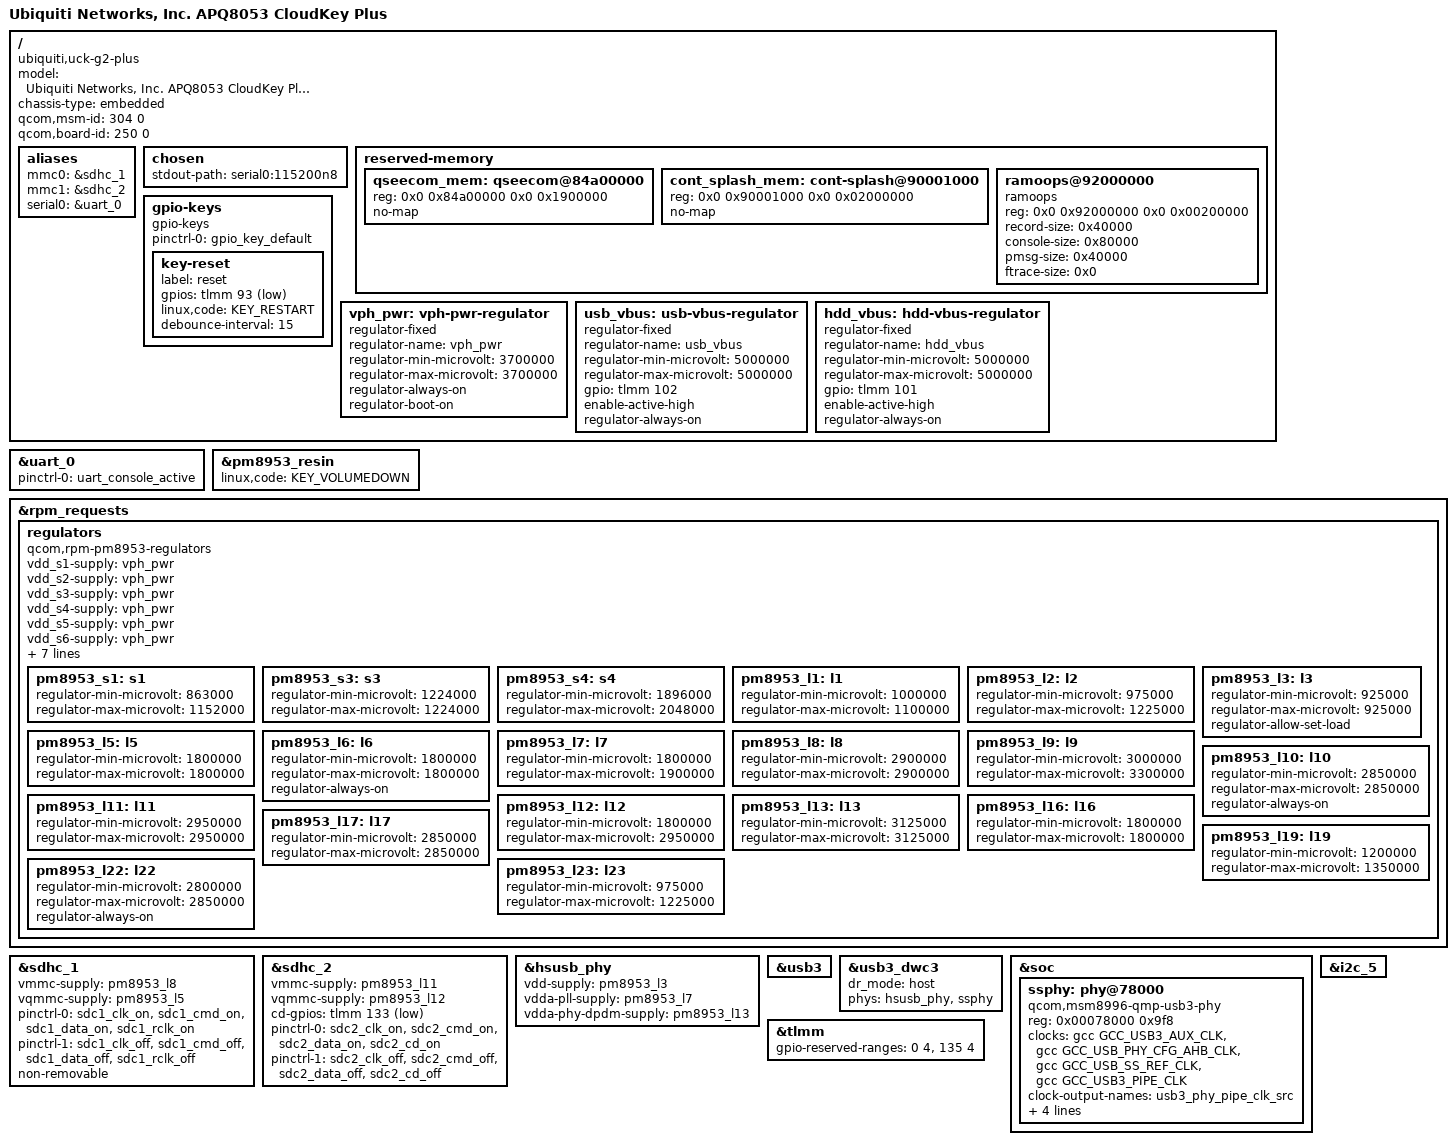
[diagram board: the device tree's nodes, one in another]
// SPDX-License-Identifier: BSD-3-Clause
/*
 * Ubiquiti UniFi Cloud Key Gen2 Plus (UCK G2 Plus, "UCKP")
 * Qualcomm APQ8053 / MSM8953 (Snapdragon 625)
 *
 * Ported to the msm8953-mainline tree from Ubiquiti's GPL vendor DTS
 * (apq8053-ck-plus.dts + msm8953-ck-plus.dtsi).  Minimal bring-up:
 * serial console, eMMC (rootfs), SD card, USB3, PMIC regulators, power/keys.
 */
/dts-v1/;

#include "msm8953.dtsi"
#include "pm8953.dtsi"
#include "pmi8950.dtsi"

/delete-node/ &cont_splash_mem;
/delete-node/ &qseecom_mem;

/ {
	model = "Ubiquiti Networks, Inc. APQ8053 CloudKey Plus";
	compatible = "ubiquiti,uck-g2-plus", "qcom,msm8953";
	chassis-type = "embedded";
	/*
	 * aboot (Qualcomm LK) matches appended DTBs on qcom,msm-id/qcom,board-id.
	 * Device socinfo reports id=304 (0x130), hw_plat=250 (0xfa) -- must match
	 * the stock DTBs or aboot errors with "Couldn't find the suitable DTB!".
	 */
	qcom,msm-id = <304 0>;
	qcom,board-id = <250 0>;

	aliases {
		mmc0 = &sdhc_1;	/* eMMC  (system + appdata) */
		mmc1 = &sdhc_2;	/* microSD */
		serial0 = &uart_0;
	};

	chosen {
		stdout-path = "serial0:115200n8";
	};

	reserved-memory {
		qseecom_mem: qseecom@84a00000 {
			reg = <0x0 0x84a00000 0x0 0x1900000>;
			no-map;
		};

		cont_splash_mem: cont-splash@90001000 {
			reg = <0x0 0x90001000 0x0 0x02000000>;
			no-map;
		};

		/*
		 * Match the vendor ramoops region so pstore survives a crash and
		 * can be read on next boot (visibility into a failed 6.19 boot).
		 * Vendor: ramoops_region@92000000, 2 MiB.
		 */
		ramoops@92000000 {
			compatible = "ramoops";
			reg = <0x0 0x92000000 0x0 0x00200000>;
			record-size = <0x40000>;
			console-size = <0x80000>;
			pmsg-size = <0x40000>;
			ftrace-size = <0x0>;
		};
	};

	gpio-keys {
		compatible = "gpio-keys";
		pinctrl-names = "default";
		pinctrl-0 = <&gpio_key_default>;

		key-reset {
			label = "reset";
			gpios = <&tlmm 93 GPIO_ACTIVE_LOW>;
			linux,code = <KEY_RESTART>;
			debounce-interval = <15>;
		};
	};

	vph_pwr: vph-pwr-regulator {
		compatible = "regulator-fixed";
		regulator-name = "vph_pwr";
		regulator-min-microvolt = <3700000>;
		regulator-max-microvolt = <3700000>;
		regulator-always-on;
		regulator-boot-on;
	};

	/* USB / SATA power enables on the UCK (from vendor DTS) */
	usb_vbus: usb-vbus-regulator {
		compatible = "regulator-fixed";
		regulator-name = "usb_vbus";
		regulator-min-microvolt = <5000000>;
		regulator-max-microvolt = <5000000>;
		gpio = <&tlmm 102 GPIO_ACTIVE_HIGH>;
		enable-active-high;
		regulator-always-on;
	};

	hdd_vbus: hdd-vbus-regulator {
		compatible = "regulator-fixed";
		regulator-name = "hdd_vbus";
		regulator-min-microvolt = <5000000>;
		regulator-max-microvolt = <5000000>;
		gpio = <&tlmm 101 GPIO_ACTIVE_HIGH>;
		enable-active-high;
		regulator-always-on;
	};
};

&uart_0 {
	status = "okay";
	pinctrl-names = "default";
	pinctrl-0 = <&uart_console_active>;
};

&pm8953_resin {
	linux,code = <KEY_VOLUMEDOWN>;
	status = "okay";
};

&rpm_requests {
	regulators {
		compatible = "qcom,rpm-pm8953-regulators";

		vdd_s1-supply = <&vph_pwr>;
		vdd_s2-supply = <&vph_pwr>;
		vdd_s3-supply = <&vph_pwr>;
		vdd_s4-supply = <&vph_pwr>;
		vdd_s5-supply = <&vph_pwr>;
		vdd_s6-supply = <&vph_pwr>;
		vdd_s7-supply = <&vph_pwr>;
		vdd_l1-supply = <&pm8953_s3>;
		vdd_l2_l3-supply = <&pm8953_s3>;
		vdd_l4_l5_l6_l7_l16_l19-supply = <&pm8953_s4>;
		vdd_l8_l11_l12_l13_l14_l15-supply = <&vph_pwr>;
		vdd_l9_l10_l17_l18_l22-supply = <&vph_pwr>;
		vdd_l23-supply = <&pm8953_s3>;

		pm8953_s1: s1 {
			regulator-min-microvolt = <863000>;
			regulator-max-microvolt = <1152000>;
		};

		pm8953_s3: s3 {
			regulator-min-microvolt = <1224000>;
			regulator-max-microvolt = <1224000>;
		};

		pm8953_s4: s4 {
			regulator-min-microvolt = <1896000>;
			regulator-max-microvolt = <2048000>;
		};

		pm8953_l1: l1 {
			regulator-min-microvolt = <1000000>;
			regulator-max-microvolt = <1100000>;
		};

		pm8953_l2: l2 {
			regulator-min-microvolt = <975000>;
			regulator-max-microvolt = <1225000>;
		};

		pm8953_l3: l3 {
			regulator-min-microvolt = <925000>;
			regulator-max-microvolt = <925000>;
			regulator-allow-set-load;
		};

		pm8953_l5: l5 {
			regulator-min-microvolt = <1800000>;
			regulator-max-microvolt = <1800000>;
		};

		pm8953_l6: l6 {
			regulator-min-microvolt = <1800000>;
			regulator-max-microvolt = <1800000>;
			regulator-always-on;
		};

		pm8953_l7: l7 {
			regulator-min-microvolt = <1800000>;
			regulator-max-microvolt = <1900000>;
		};

		pm8953_l8: l8 {
			regulator-min-microvolt = <2900000>;
			regulator-max-microvolt = <2900000>;
		};

		pm8953_l9: l9 {
			regulator-min-microvolt = <3000000>;
			regulator-max-microvolt = <3300000>;
		};

		pm8953_l10: l10 {
			regulator-min-microvolt = <2850000>;
			regulator-max-microvolt = <2850000>;
			regulator-always-on;
		};

		pm8953_l11: l11 {
			regulator-min-microvolt = <2950000>;
			regulator-max-microvolt = <2950000>;
		};

		pm8953_l12: l12 {
			regulator-min-microvolt = <1800000>;
			regulator-max-microvolt = <2950000>;
		};

		pm8953_l13: l13 {
			regulator-min-microvolt = <3125000>;
			regulator-max-microvolt = <3125000>;
		};

		pm8953_l16: l16 {
			regulator-min-microvolt = <1800000>;
			regulator-max-microvolt = <1800000>;
		};

		pm8953_l17: l17 {
			regulator-min-microvolt = <2850000>;
			regulator-max-microvolt = <2850000>;
		};

		pm8953_l19: l19 {
			regulator-min-microvolt = <1200000>;
			regulator-max-microvolt = <1350000>;
		};

		pm8953_l22: l22 {
			regulator-min-microvolt = <2800000>;
			regulator-max-microvolt = <2850000>;
			regulator-always-on;
		};

		pm8953_l23: l23 {
			regulator-min-microvolt = <975000>;
			regulator-max-microvolt = <1225000>;
		};
	};
};

/* eMMC: system rootfs (p44/p46/p47) + the internal 1TB disk */
&sdhc_1 {
	vmmc-supply = <&pm8953_l8>;
	vqmmc-supply = <&pm8953_l5>;

	pinctrl-names = "default", "sleep";
	pinctrl-0 = <&sdc1_clk_on &sdc1_cmd_on &sdc1_data_on &sdc1_rclk_on>;
	pinctrl-1 = <&sdc1_clk_off &sdc1_cmd_off &sdc1_data_off &sdc1_rclk_off>;

	non-removable;
	status = "okay";
};

/* microSD slot */
&sdhc_2 {
	vmmc-supply = <&pm8953_l11>;
	vqmmc-supply = <&pm8953_l12>;

	cd-gpios = <&tlmm 133 GPIO_ACTIVE_LOW>;

	pinctrl-names = "default", "sleep";
	pinctrl-0 = <&sdc2_clk_on &sdc2_cmd_on &sdc2_data_on &sdc2_cd_on>;
	pinctrl-1 = <&sdc2_clk_off &sdc2_cmd_off &sdc2_data_off &sdc2_cd_off>;

	status = "okay";
};

&hsusb_phy {
	vdd-supply = <&pm8953_l3>;
	vdda-pll-supply = <&pm8953_l7>;
	vdda-phy-dpdm-supply = <&pm8953_l13>;

	status = "okay";
};

&usb3 {
	status = "okay";
};

&usb3_dwc3 {
	/*
	 * The mainline dtsi sets `usb-role-switch` with no role-switch-default-mode.
	 * dwc3_drd_init() -> dwc3_setup_role_switch(): no default mode =>
	 * USB_DR_MODE_UNKNOWN => controller defaults to PERIPHERAL. That kills the
	 * internal USB hub, so the AX88179 NIC never enumerates and the box looks
	 * dead. Drop the property (what the mainline msm8953 phones do) so
	 * dr_mode="host" actually takes effect.
	 */
	/delete-property/ usb-role-switch;
	/* The UCK's NIC + SATA live on the SuperSpeed root hub; the mainline dtsi
	 * caps the controller at high-speed, so enable SuperSpeed with the QMP PHY. */
	/delete-property/ maximum-speed;
	dr_mode = "host";
	phys = <&hsusb_phy>, <&ssphy>;
	phy-names = "usb2-phy", "usb3-phy";
};

/*
 * USB3 SuperSpeed (QMP) PHY on the UCK.
 *
 * The UCK has no on-SoC Ethernet: LAN is an ASIX AX88179 USB3 NIC behind a
 * TI USB3 hub on the SuperSpeed root hub (the SATA bridge too). Mainline
 * msm8953 has NO SuperSpeed PHY node and no QMP driver entry for it, so the
 * SS hub never enumerates -> no NIC -> no network. This node provides it,
 * using the mainline QMP v3 driver (msm8996 is the same QMP generation) and
 * the SS PHY register block at 0x78000 (from Ubiquiti's vendor DTS).
 */
&soc {
	ssphy: phy@78000 {
		compatible = "qcom,msm8996-qmp-usb3-phy";
		reg = <0x00078000 0x9f8>;

		clocks = <&gcc GCC_USB3_AUX_CLK>,
			 <&gcc GCC_USB_PHY_CFG_AHB_CLK>,
			 <&gcc GCC_USB_SS_REF_CLK>,
			 <&gcc GCC_USB3_PIPE_CLK>;
		clock-names = "aux", "cfg_ahb", "ref", "pipe";

		clock-output-names = "usb3_phy_pipe_clk_src";
		#clock-cells = <0>;
		#phy-cells = <0>;

		resets = <&gcc GCC_USB3_PHY_BCR>,
			 <&gcc GCC_USB3PHY_PHY_BCR>;
		reset-names = "phy_phy", "phy";

		vdda-phy-supply = <&pm8953_l3>;
		vdda-pll-supply = <&pm8953_l7>;

		status = "okay";
	};
};

/* front-panel LEDs (LP5562 on i2c_5) and reset key pinctrl */
&i2c_5 {
	status = "okay";
};

&tlmm {
	gpio-reserved-ranges = <0 4>, <135 4>;
};
